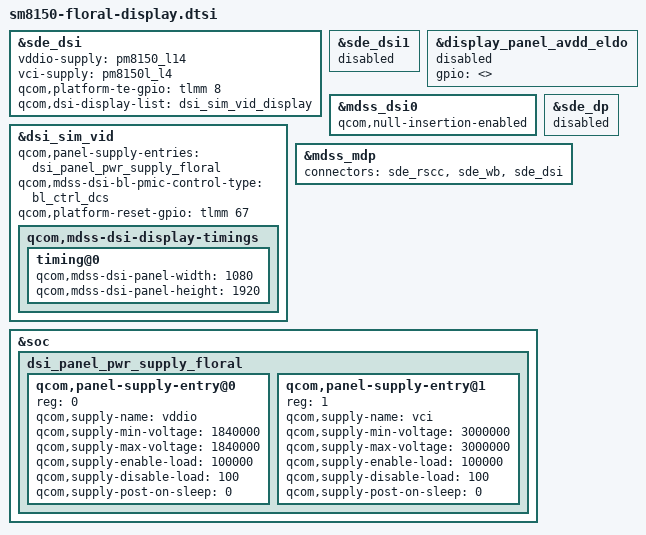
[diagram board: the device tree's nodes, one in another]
/* Copyright (c) 2018, The Linux Foundation. All rights reserved.
 *
 * This program is free software; you can redistribute it and/or modify
 * it under the terms of the GNU General Public License version 2 and
 * only version 2 as published by the Free Software Foundation.
 *
 * This program is distributed in the hope that it will be useful,
 * but WITHOUT ANY WARRANTY; without even the implied warranty of
 * MERCHANTABILITY or FITNESS FOR A PARTICULAR PURPOSE.  See the
 * GNU General Public License for more details.
 */

#include "../qcom/sm8150-sde-display.dtsi"

#include <dt-bindings/clock/mdss-10nm-pll-clk.h>

&sde_dsi {
	vddio-supply = <&pm8150_l14>;
	vci-supply = <&pm8150l_l4>;
	qcom,platform-te-gpio = <&tlmm 8 0>;

	/delete-property/ vdd-supply;
	/delete-property/ lab-supply;
	/delete-property/ ibb-supply;

	qcom,dsi-display-list = <&dsi_sim_vid_display>;
};

&sde_dsi1 {
    status = "disabled";
};

// Disable control of incorrect gpio pin 130
&display_panel_avdd_eldo {
	gpio = <>;
	status = "disabled";
};

// Without the line below, display corruption occurs.
&mdss_dsi0 {
	qcom,null-insertion-enabled;
};

&dsi_sim_vid {
	qcom,panel-supply-entries = <&dsi_panel_pwr_supply_floral>;
	qcom,mdss-dsi-bl-pmic-control-type = "bl_ctrl_dcs";
	qcom,platform-reset-gpio = <&tlmm 67 0>;
	qcom,mdss-dsi-display-timings {
		timing@0 {
			qcom,mdss-dsi-panel-width = <1080>;
			qcom,mdss-dsi-panel-height = <1920>;
		};
	};
};

&sde_dp {
	status = "disabled";
};

&mdss_mdp {
	connectors = <&sde_rscc &sde_wb &sde_dsi>;
};

&soc {
	dsi_panel_pwr_supply_floral: dsi_panel_pwr_supply_floral {
		#address-cells = <1>;
		#size-cells = <0>;

		qcom,panel-supply-entry@0 {
			reg = <0>;
			qcom,supply-name = "vddio";
			qcom,supply-min-voltage = <1840000>;
			qcom,supply-max-voltage = <1840000>;
			qcom,supply-enable-load = <100000>;
			qcom,supply-disable-load = <100>;
			qcom,supply-post-on-sleep = <0>;
		};

		qcom,panel-supply-entry@1 {
			reg = <1>;
			qcom,supply-name = "vci";
			qcom,supply-min-voltage = <3000000>;
			qcom,supply-max-voltage = <3000000>;
			qcom,supply-enable-load = <100000>;
			qcom,supply-disable-load = <100>;
			qcom,supply-post-on-sleep = <0>;
		};
	};
};
